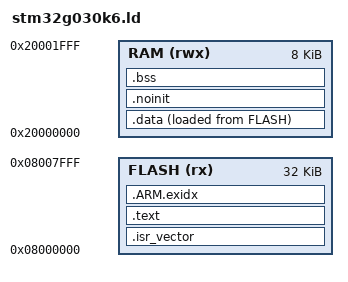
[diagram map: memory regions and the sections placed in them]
/* SPDX-FileCopyrightText: 2026 BFU Electronics LTD
 * SPDX-License-Identifier: Apache-2.0 */
/* STM32G030K6: 32K flash, 8K RAM */
MEMORY
{
  FLASH (rx)  : ORIGIN = 0x08000000, LENGTH = 32K
  RAM   (rwx) : ORIGIN = 0x20000000, LENGTH = 8K
}

ENTRY(Reset_Handler)
_estack = ORIGIN(RAM) + LENGTH(RAM);
_min_stack = 0x400;

SECTIONS
{
  .isr_vector :
  {
    . = ALIGN(4);
    KEEP(*(.isr_vector))
  } > FLASH

  .text :
  {
    . = ALIGN(4);
    *(.text .text.*)
    *(.rodata .rodata.*)
    *(.glue_7) *(.glue_7t)
    KEEP(*(.init)) KEEP(*(.fini))
    . = ALIGN(4);
  } > FLASH

  .ARM.exidx : { *(.ARM.exidx* .gnu.linkonce.armexidx.*) } > FLASH

  _sidata = LOADADDR(.data);
  .data :
  {
    . = ALIGN(4);
    _sdata = .;
    *(.data .data.*)
    . = ALIGN(4);
    _edata = .;
  } > RAM AT> FLASH

  /* survives reset: bootloader request flag; never initialised by startup */
  .noinit (NOLOAD) :
  {
    . = ALIGN(4);
    *(.noinit .noinit.*)
    . = ALIGN(4);
  } > RAM

  .bss :
  {
    . = ALIGN(4);
    _sbss = .;
    *(.bss .bss.*)
    *(COMMON)
    . = ALIGN(4);
    _ebss = .;
  } > RAM

  ASSERT(_ebss + _min_stack <= _estack, "RAM overflow: not enough room for the stack")

  /DISCARD/ : { *(.ARM.attributes) }
}
